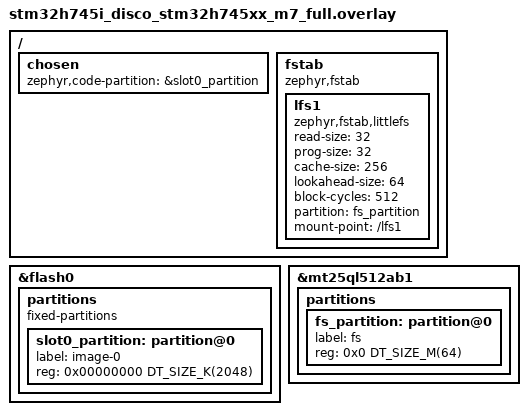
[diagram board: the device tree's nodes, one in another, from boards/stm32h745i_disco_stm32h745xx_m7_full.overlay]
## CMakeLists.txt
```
# SPDX-License-Identifier: Apache-2.0

cmake_minimum_required(VERSION 3.20.0)

option(CM_ENABLE_BOOTLOADER              "Enable bootloader support."                    OFF)
option(CM_ENABLE_CUSTOM_HEAP             "Enable custom heap."                           OFF)
option(CM_ENABLE_MEM_PROFILE             "Enable heap profiling."                        OFF)
option(CM_ENABLE_STACK_PROFILE           "Enable stack profiling."                       OFF)

if(DEFINED ENV{ZEPHYR_DNS_SERVER} OR DEFINED ENV{ZEPHYR_DNS_SERVER_2} OR DEFINED ENV{ZEPHYR_HOST_IP})
  set(EXTRA_CONF_CONTENT "")
  if(DEFINED ENV{ZEPHYR_DNS_SERVER})
    string(APPEND EXTRA_CONF_CONTENT "CONFIG_DNS_SERVER1=\"$ENV{ZEPHYR_DNS_SERVER}:53\"\n")
  endif()
  if(DEFINED ENV{ZEPHYR_DNS_SERVER_2})
    string(APPEND EXTRA_CONF_CONTENT "CONFIG_DNS_SERVER2=\"$ENV{ZEPHYR_DNS_SERVER_2}:53\"\n")
  endif()
  if(DEFINED ENV{ZEPHYR_HOST_IP})
    string(APPEND EXTRA_CONF_CONTENT "CONFIG_NET_CONFIG_PEER_IPV4_ADDR=\"$ENV{ZEPHYR_HOST_IP}\"\n")
  endif()
  set(ENV_CONF_FILE ${CMAKE_BINARY_DIR}/env_override.conf)
  file(WRITE ${ENV_CONF_FILE} ${EXTRA_CONF_CONTENT})
  set(CONF_FILE "prj.conf;${ENV_CONF_FILE}")
endif()

find_package(Zephyr REQUIRED HINTS $ENV{ZEPHYR_BASE})
project(trustedge_sample C)


set(MSS_DIR  "${CMAKE_CURRENT_SOURCE_DIR}/../../..")
set(MSS_SRC_DIR "${MSS_DIR}/src")
set(TRUSTCORE_LIB_DIR "${MSS_DIR}/bin_static")

include_directories(
  ${MSS_SRC_DIR}
  ${MSS_SRC_DIR}/trustedge
)

function(builder_add_flags FLAGS_VAR)
    message("----------------")
    foreach(FLAGS_FILE IN LISTS ARGN)
        message("${FLAGS_VAR} - adding flags in ${FLAGS_FILE}")
        file(STRINGS ${FLAGS_FILE} FLAGS_TO_ADD)
        set(FLAGS_LIST "${FLAGS_LIST} ${FLAGS_TO_ADD}")
    endforeach()
    set(${FLAGS_VAR} "${${FLAGS_VAR}} ${FLAGS_LIST}" PARENT_SCOPE)
endfunction()

function(builder_finalize_flags FLAGS_VAR)
    message("----------------")
    foreach(FLAG ${${FLAGS_VAR}})
        string(STRIP "${STRIPPED_FLAGS} ${FLAG}" STRIPPED_FLAGS)
    endforeach()
    set(${FLAGS_VAR} "${STRIPPED_FLAGS}" PARENT_SCOPE)
    message("${FLAGS_VAR} = ${${FLAGS_VAR}}")
endfunction()

if ("${BOARD}" STREQUAL "native_sim")
  add_definitions("-D__ENABLE_DIGICERT_NATIVE_SIM__")
elseif ("${BOARD}" STREQUAL "esp32s3_devkitc")
  add_definitions("-D__ENABLE_DIGICERT_ESP32S3__")
endif()

if (CM_ENABLE_BOOTLOADER)
  add_definitions("-D__ENABLE_DIGICERT_BOOTLOADER_SUPPORT__")
endif()

if (CM_ENABLE_MEM_PROFILE)
  add_definitions("-D__ENABLE_DIGICERT_MEM_PROFILE__")
endif()

if (CM_ENABLE_STACK_PROFILE)
  add_definitions("-D__ENABLE_DIGICERT_STACK_PROFILE__")
endif()

if (CM_ENABLE_CUSTOM_HEAP)
  add_definitions("-D__ENABLE_DIGICERT_CUSTOM_MALLOC__")
endif()

target_compile_definitions(app PRIVATE "-DIMAGE_NAME=\"${TRUSTEDGE_IMAGE_NAME}\"")

builder_add_flags(MOCANA_FLAGS "${CMAKE_CURRENT_SOURCE_DIR}/digicert_flags.txt")
builder_finalize_flags(MOCANA_FLAGS)

add_definitions("${MOCANA_FLAGS}")

# Add optimization compile options
  # target_compile_options(app PUBLIC
  #   -Oz
  #   -ffunction-sections
  #   -fdata-sections
  #   -flto
  #   -fmerge-all-constants
  #   -fno-jump-tables
  #   -fno-tree-switch-conversion
  #   -finline-functions
  #   -finline-small-functions
  # )

# Add optimization link options
  # target_link_options(app PUBLIC
  #   -Wl,--gc-sections
  #   -Wl,--relax
  #   -Wl,--sort-section=alignment
  #   -Wl,--sort-common
  #   -Wl,--strip-discarded
  #   -Wl,--orphan-handling=place
  #   -Wl,--print-memory-usage
  # )

if("${BOARD}" STREQUAL "esp32s3_devkitc")
  target_link_options(app PUBLIC
    -Wl,--wrap=malloc
    -Wl,--wrap=free
    -Wl,--wrap=calloc
    -Wl,--wrap=TRUSTEDGE_utilsGetHostByName
  )
endif()

set(app_sources src/main.c src/dns.c)
target_sources(app PRIVATE ${app_sources})

if("${BOARD}" STREQUAL "esp32s3_devkitc")
  target_sources(app PRIVATE src/heap_allocator.c)
endif()

file(GLOB EXTERNAL_LIBS "${TRUSTCORE_LIB_DIR}/*.a")

foreach(lib_path ${EXTERNAL_LIBS})
  get_filename_component(lib_name ${lib_path} NAME_WE)
  message(STATUS "Linking library: ${lib_name} => ${lib_path}")

  add_library(${lib_name} STATIC IMPORTED GLOBAL)
  set_target_properties(${lib_name} PROPERTIES IMPORTED_LOCATION ${lib_path})
  target_link_libraries(app PUBLIC ${lib_name})
endforeach()
```

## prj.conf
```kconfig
# Set the name of target binary
CONFIG_KERNEL_BIN_NAME="trustedge"
#CONFIG_DEBUG=y
#CONFIG_SIZE_OPTIMIZATIONS_AGGRESSIVE=y

# the number of bytes in the arena for C library malloc
CONFIG_COMMON_LIBC_MALLOC=y
#CONFIG_COMMON_LIBC_MALLOC_ARENA_SIZE=102000

CONFIG_REQUIRES_FULL_LIBC=y

CONFIG_ENTROPY_GENERATOR=y
CONFIG_TEST_RANDOM_GENERATOR=y

CONFIG_POSIX_API=y

# for enabling poxis threads
CONFIG_POSIX_THREADS=y # pthread
CONFIG_POSIX_TIMERS=y

CONFIG_INIT_STACKS=y
CONFIG_THREAD_STACK_INFO=y

CONFIG_DYNAMIC_THREAD=y
CONFIG_DYNAMIC_THREAD_POOL_SIZE=6
CONFIG_POSIX_THREAD_KEYS_MAX=20
CONFIG_POSIX_THREAD_THREADS_MAX=20
CONFIG_MAX_PTHREAD_MUTEX_COUNT=20
CONFIG_MAX_PTHREAD_COND_COUNT=20

# Enable thread awareness for debugging tools supporting it
CONFIG_DEBUG_THREAD_INFO=y

CONFIG_LOG=y

CONFIG_SHELL=y
CONFIG_SHELL_LOG_LEVEL_INF=y

CONFIG_FILE_SYSTEM=y
CONFIG_FILE_SYSTEM_SHELL=y

CONFIG_FILE_SYSTEM_LITTLEFS=y
CONFIG_FLASH_MAP=y
CONFIG_FLASH=y

# Networking config
#CONFIG_NET_SOCKETS_LOG_LEVEL_DBG=n
CONFIG_NET_SOCKETS=y
CONFIG_NETWORKING=y
CONFIG_NET_IPV4=y
CONFIG_NET_DHCPV4=y
CONFIG_NET_IPV6=n
CONFIG_NET_IF_MAX_IPV4_COUNT=2
CONFIG_NET_TCP=y
CONFIG_NET_LOG=n
CONFIG_NET_MAX_CONTEXTS=10

CONFIG_NET_SHELL=y

CONFIG_NET_CONFIG_SETTINGS=y
CONFIG_NET_CONFIG_NEED_IPV4=y

CONFIG_NET_MAX_CONN=10

CONFIG_ZVFS_POLL_MAX=10
CONFIG_ZVFS_OPEN_MAX=10
# Enable the DNS resolver
CONFIG_DNS_RESOLVER=y
# Enable additional buffers
CONFIG_DNS_RESOLVER_ADDITIONAL_BUF_CTR=5
# Enable additional queries
CONFIG_DNS_RESOLVER_ADDITIONAL_QUERIES=2
# Enable mDNS support
CONFIG_MDNS_RESOLVER=y
# Enable LLMNR support
CONFIG_LLMNR_RESOLVER=n

CONFIG_DNS_RESOLVER_MAX_SERVERS=2
CONFIG_DNS_SERVER_IP_ADDRESSES=y
CONFIG_DNS_NUM_CONCUR_QUERIES=5

CONFIG_DNS_SERVER1="8.8.8.8:53"
CONFIG_DNS_SERVER2="1.1.1.1:53"

CONFIG_NET_PKT_RX_COUNT=32
CONFIG_NET_PKT_TX_COUNT=32
CONFIG_NET_BUF_RX_COUNT=32
CONFIG_NET_BUF_TX_COUNT=32

CONFIG_NET_TCP_LOG_LEVEL_DBG=n

CONFIG_HWINFO=y

# Set current time from ntp server
CONFIG_SNTP=y
CONFIG_SNTP_LOG_LEVEL_DBG=n
CONFIG_NET_CONFIG_CLOCK_SNTP_INIT=y
CONFIG_NET_CONFIG_SNTP_INIT_RESYNC=y
CONFIG_NET_CONFIG_SNTP_INIT_SERVER="north-america.pool.ntp.org"

CONFIG_FRAME_POINTER=y

CONFIG_THREAD_NAME=y
#CONFIG_THREAD_ANALYZER=y
#CONFIG_THREAD_ANALYZER_AUTO=y
#CONFIG_THREAD_ANALYZER_RUN_UNLOCKED=y
```

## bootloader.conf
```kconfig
CONFIG_BOOTLOADER_MCUBOOT=y
CONFIG_MCUBOOT_SIGNATURE_KEY_FILE="bootloader/mcuboot/root-rsa-2048.pem"

# CONFIG_IMG_MANAGER depends on this
CONFIG_STREAM_FLASH=y

# CONFIG_MCUBOOT_IMG_MANAGER depends on this, already set above
CONFIG_FLASH_MAP=y

# required for including <zephyr/dfu/mcuboot.h>
CONFIG_IMG_MANAGER=y
CONFIG_MCUBOOT_IMG_MANAGER=y

CONFIG_IMG_BLOCK_BUF_SIZE=32

CONFIG_IMG_ENABLE_IMAGE_CHECK=y
#CONFIG_IMG_ENABLE_IMAGE_CHECK=y
CONFIG_MCUBOOT_UTIL_LOG_LEVEL_DBG=y
#CONFIG_IMG_MANAGER=y
```

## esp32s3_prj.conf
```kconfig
CONFIG_ESP_SPIRAM_HEAP_SIZE=4194304
CONFIG_COMMON_LIBC_MALLOC=n
CONFIG_HEAP_MEM_POOL_SIZE=25000
CONFIG_DYNAMIC_THREAD=y
CONFIG_DYNAMIC_THREAD_POOL_SIZE=4
CONFIG_DYNAMIC_THREAD_ALLOC=y
CONFIG_DYNAMIC_THREAD_STACK_SIZE=8000
CONFIG_MAIN_STACK_SIZE=8192
CONFIG_STACK_CANARIES=y
CONFIG_STACK_SENTINEL=y
CONFIG_SHELL_BACKEND_SERIAL_TX_RING_BUFFER_SIZE=192
CONFIG_SHELL_BACKEND_SERIAL_RX_RING_BUFFER_SIZE=192
CONFIG_SYSTEM_WORKQUEUE_STACK_SIZE=4096
CONFIG_LOG_PROCESS_THREAD_STACK_SIZE=4096
CONFIG_SHELL_STACK_SIZE=5500
CONFIG_LOG_BUFFER_SIZE=8192
CONFIG_LOG_FUNC_NAME_PREFIX_DBG=n
CONFIG_SHELL_LOG_BACKEND=y
CONFIG_LOG_PROCESS_TRIGGER_THRESHOLD=1
CONFIG_LOG_BACKEND_FS=y
CONFIG_LOG_BACKEND_FS_AUTOSTART=n
CONFIG_LOG_BACKEND_FS_FILE_SIZE=1024000
CONFIG_LOG_BACKEND_FS_FILES_LIMIT=5
CONFIG_LOG_BACKEND_FS_DIR="/lfs1/log"
CONFIG_LOG_CMDS=y
CONFIG_INIT_STACKS=y
CONFIG_KERNEL_SHELL=y
CONFIG_THREAD_MONITOR=y
CONFIG_BOOT_BANNER=y
CONFIG_THREAD_NAME=y
CONFIG_DEVICE_SHELL=n
CONFIG_DATE_SHELL=n
CONFIG_IDLE_STACK_SIZE=1024
CONFIG_STATS=y
CONFIG_STATS_SHELL=y
CONFIG_SIZE_OPTIMIZATIONS_AGGRESSIVE=y
CONFIG_REBOOT=y
CONFIG_FS_LITTLEFS_READ_SIZE=1024
CONFIG_FS_LITTLEFS_PROG_SIZE=1024
CONFIG_FS_LITTLEFS_CACHE_SIZE=1024
CONFIG_FS_LITTLEFS_LOOKAHEAD_SIZE=512
CONFIG_FS_LITTLEFS_BLOCK_CYCLES=16
CONFIG_ESP_SPIRAM=y
CONFIG_ESP_SPIRAM_SIZE=8388608
CONFIG_SPIRAM_MODE_OCT=y
CONFIG_SHARED_MULTI_HEAP=y
CONFIG_ESP32S3_DATA_CACHE_64KB=y
CONFIG_ESP32S3_DATA_CACHE_LINE_64B=y
CONFIG_SPIRAM_TYPE_ESPPSRAM64=y
CONFIG_ESP32_WIFI_NET_ALLOC_SPIRAM=y
CONFIG_ESP_WIFI_HEAP_SPIRAM=y
CONFIG_BOOTLOADER_MCUBOOT=y
CONFIG_WIFI=y
CONFIG_NET_SHELL=y
CONFIG_SNTP=y
CONFIG_SNTP_LOG_LEVEL_INF=y
CONFIG_NET_CONFIG_CLOCK_SNTP_INIT=y
CONFIG_NET_CONFIG_SNTP_INIT_RESYNC=y
CONFIG_NET_CONNECTION_MANAGER=y
CONFIG_NET_CONFIG_SNTP_INIT_USE_CONNECTION_MANAGER=y
CONFIG_NET_CONFIG_SNTP_INIT_SERVER="time.google.com"
CONFIG_NET_DHCPV4=y
CONFIG_NET_LOG=y
CONFIG_NET_L2_WIFI_SHELL=y
CONFIG_DNS_RESOLVER=y
CONFIG_ESP32_WIFI_AMPDU_TX_ENABLED=y
CONFIG_ESP32_WIFI_TX_BA_WIN=32
CONFIG_NET_TCP_KEEPALIVE=y
CONFIG_NET_L2_WIFI_MGMT=y
CONFIG_NET_TCP_WORKQ_STACK_SIZE=8192
CONFIG_NET_TX_STACK_SIZE=8192
CONFIG_NET_RX_STACK_SIZE=8192
CONFIG_NET_BUF_RX_COUNT=512
CONFIG_NET_BUF_TX_COUNT=512
CONFIG_NET_PKT_RX_COUNT=512
CONFIG_NET_PKT_TX_COUNT=512
CONFIG_ESP32_WIFI_CACHE_TX_BUFFER_NUM=128


# CONFIG_ESP32_WIFI_DYNAMIC_TX_BUFFER=y
# CONFIG_ESP32_WIFI_DYNAMIC_TX_BUFFER_NUM=128
# CONFIG_ESP32_WIFI_DYNAMIC_RX_MGMT_BUFFER=y
# CONFIG_ESP32_WIFI_DYNAMIC_RX_BUFFER_NUM=128
# CONFIG_ESP32_WIFI_STATIC_TX_BUFFER=y
# CONFIG_ESP32_WIFI_STATIC_TX_BUFFER_NUM=64
# CONFIG_NET_CONNECTION_MANAGER=y
# CONFIG_NET_TCP_RECV_QUEUE_TIMEOUT=10000
# CONFIG_NET_TCP_MAX_SEND_WINDOW_SIZE=65535
# CONFIG_NET_TCP_MAX_RECV_WINDOW_SIZE=65535
# CONFIG_THREAD_ANALYZER=y
# CONFIG_THREAD_ANALYZER_AUTO=y
# CONFIG_THREAD_ANALYZER_AUTO_INTERVAL=5
# CONFIG_COMMON_LIBC_MALLOC_ARENA_SIZE=0
# CONFIG_NET_MAX_CONN=10
# CONFIG_NET_MAX_CONTEXTS=15
# CONFIG_ESP32_WIFI_CACHE_TX_BUFFER_NUM=64
# CONFIG_NET_STATISTICS=y
# CONFIG_NET_STATISTICS_WIFI=y
# CONFIG_NET_MGMT_EVENT_QUEUE_SIZE=10
# CONFIG_MDNS_RESOLVER=y
# CONFIG_NET_HOSTNAME_ENABLE=y
# CONFIG_NET_HOSTNAME="esp32-client"
# CONFIG_NET_DEBUG_NET_PKT_ALLOC=y
# CONFIG_FILE_SYSTEM_MKFS=y
# CONFIG_ESP32S3_UNIVERSAL_MAC_ADDRESSES_FOUR=y
# CONFIG_NET_IF_UNICAST_IPV4_ADDR_COUNT=2
# CONFIG_ESP32_WIFI_STA_AUTO_DHCPV4=y
# CONFIG_SPIRAM_FETCH_INSTRUCTIONS=y
# CONFIG_EARLY_CONSOLE=y
# CONFIG_NET_MGMT_EVENT_QUEUE_TIMEOUT=5000
# CONFIG_NET_MGMT_EVENT_QUEUE_SIZE=8
# CONFIG_POSIX_API=y
# CONFIG_POSIX_THREADS=y
# CONFIG_POSIX_TIMERS=y
# CONFIG_THREAD_STACK_INFO=y
# CONFIG_POSIX_THREAD_KEYS_MAX=20
# CONFIG_POSIX_THREAD_THREADS_MAX=20
# CONFIG_MAX_PTHREAD_MUTEX_COUNT=20
# CONFIG_MAX_PTHREAD_COND_COUNT=20
# CONFIG_DEBUG_THREAD_INFO=y
# CONFIG_LOG=y
# CONFIG_SHELL=y
# CONFIG_SHELL_LOG_LEVEL_INF=y
# CONFIG_FILE_SYSTEM=y
# CONFIG_FILE_SYSTEM_SHELL=y
# CONFIG_FILE_SYSTEM_LITTLEFS=y
# CONFIG_FLASH_MAP=y
# CONFIG_FLASH=y
# CONFIG_NET_SOCKETS_LOG_LEVEL_DBG=n
# CONFIG_NET_IF_MAX_IPV4_COUNT=2
# CONFIG_NET_CONFIG_SETTINGS=y
# CONFIG_NET_CONFIG_NEED_IPV4=y
# CONFIG_NET_CONFIG_MY_IPV4_ADDR="192.168.1.142"
# CONFIG_NET_CONFIG_PEER_IPV4_ADDR="192.168.1.124"
# CONFIG_NET_CONFIG_MY_IPV4_GW="192.168.1.1"
# CONFIG_PRINTK=y
# CONFIG_RTC=y
# CONFIG_ZTEST_STACK_SIZE=4096
# CONFIG_NET_TCP=y
# CONFIG_LOG_BACKEND_UART=y
# CONFIG_LOG_PROCESS_THREAD_CUSTOM_PRIORITY=y
# CONFIG_LOG_MODE_OVERFLOW=y
# CONFIG_LOG_MODE_DEFERRED=y
# CONFIG_LOG_RUNTIME_FILTERING=y
# CONFIG_ESP32_WIFI_DEBUG_PRINT=n
# CONFIG_ESP32_WIFI_CACHE_TX_BUFFER_NUM=16
# CONFIG_ESP32_WIFI_RX_BA_WIN=3
# CONFIG_SPIRAM_SPEED_80M=y
# CONFIG_ESPTOOLPY_FLASHFREQ_80M=y
# CONFIG_NET_SOCKETS=y
# CONFIG_DNS_SERVER1="172.16.23.141:53"
# CONFIG_NET_BUF_VARIABLE_DATA_SIZE=n
# CONFIG_NET_BUF=y
# CONFIG_NET_BUF_POOL_USAGE=y
# CONFIG_NET_PKT_BUF_RX_DATA_POOL_SIZE=16384
# CONFIG_NET_PKT_BUF_TX_DATA_POOL_SIZE=16384
# CONFIG_NET_BUF_FIXED_DATA_SIZE=y
# CONFIG_ZVFS_POLL_MAX=15
# CONFIG_ZVFS_OPEN_MAX=15
# CONFIG_NET_BUF_DATA_SIZE=512
```

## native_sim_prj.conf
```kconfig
# Set the name of target binary
CONFIG_KERNEL_BIN_NAME="trustedge"
CONFIG_DEBUG=n

# the number of bytes in the arena for C library malloc
CONFIG_COMMON_LIBC_MALLOC=y
CONFIG_COMMON_LIBC_MALLOC_ARENA_SIZE=1048576

CONFIG_REQUIRES_FULL_LIBC=y

# number of bytes for k_malloc
CONFIG_HEAP_MEM_POOL_SIZE=1048576

# Networking config
CONFIG_NET_SOCKETS=y
CONFIG_NETWORKING=y
CONFIG_ENTROPY_GENERATOR=y
CONFIG_TEST_RANDOM_GENERATOR=y
CONFIG_POSIX_SEMAPHORES=y
CONFIG_POSIX_AEP_CHOICE_PSE51=y
CONFIG_POSIX_MESSAGE_PASSING=y
CONFIG_POSIX_NETWORKING=y
CONFIG_POSIX_SIGNALS=y
CONFIG_POSIX_REALTIME_SIGNALS=y
CONFIG_POSIX_API=y
CONFIG_REBOOT=y

# for enabling poxis threads
CONFIG_POSIX_THREADS=y
CONFIG_THREAD_STACK_INFO=y
CONFIG_DYNAMIC_THREAD=y

CONFIG_DYNAMIC_THREAD_POOL_SIZE=20
CONFIG_POSIX_THREAD_KEYS_MAX=20
CONFIG_POSIX_THREAD_THREADS_MAX=20
CONFIG_MAX_PTHREAD_MUTEX_COUNT=20
CONFIG_MAX_PTHREAD_COND_COUNT=20

# Enable thread awareness for debugging tools supporting it
CONFIG_DEBUG_THREAD_INFO=y

CONFIG_LOG=y

CONFIG_FLASH=y

CONFIG_SHELL=y
CONFIG_SHELL_LOG_LEVEL_INF=y

CONFIG_FILE_SYSTEM=y
CONFIG_FILE_SYSTEM_SHELL=y

CONFIG_FILE_SYSTEM_LITTLEFS=y
CONFIG_FLASH_MAP=y

CONFIG_NET_SHELL=y

# Networking config
CONFIG_NET_IPV4=y
CONFIG_NET_IF_MAX_IPV4_COUNT=2
CONFIG_NET_IF_MAX_IPV6_COUNT=2
CONFIG_NET_TCP=y
CONFIG_NET_LOG=y

CONFIG_INIT_STACKS=y
# Network address config

CONFIG_NET_CONFIG_SETTINGS=y
CONFIG_NET_CONFIG_NEED_IPV4=y
CONFIG_NET_CONFIG_MY_IPV4_ADDR="10.166.125.155"
CONFIG_ETH_NATIVE_POSIX=n
CONFIG_NET_DRIVERS=y
CONFIG_NET_SOCKETS=y
CONFIG_NET_SOCKETS_OFFLOAD=y
CONFIG_NET_NATIVE_OFFLOADED_SOCKETS=y

CONFIG_DNS_RESOLVER=y
CONFIG_DNS_SERVER_IP_ADDRESSES=y
CONFIG_DNS_SERVER1="8.8.8.8"

CONFIG_HWINFO=y

CONFIG_MAIN_STACK_SIZE=4096

# RSA_setPublicKeyData had RSA_N optimized out
CONFIG_NO_OPTIMIZATIONS=y

# Set current time from ntp server
CONFIG_SNTP=y
CONFIG_NET_CONFIG_CLOCK_SNTP_INIT=y
CONFIG_NET_CONFIG_SNTP_INIT_RESYNC=y
CONFIG_POSIX_TIMERS=y
CONFIG_NET_CONFIG_SNTP_INIT_SERVER="north-america.pool.ntp.org"

# Assign a static MAC to device
CONFIG_ETH_NATIVE_POSIX_MAC_ADDR="00:11:22:33:44:55"
CONFIG_ETH_NATIVE_POSIX_RANDOM_MAC=n
```

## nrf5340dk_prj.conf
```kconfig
# Set the name of target binary
#CONFIG_KERNEL_BIN_NAME="trustedge"
#CONFIG_DEBUG=y
#CONFIG_SIZE_OPTIMIZATIONS_AGGRESSIVE=y

# heap and stack tracking requires additional file handles
CONFIG_FS_LITTLEFS_NUM_FILES=8
CONFIG_DYNAMIC_THREAD_STACK_SIZE=10240
CONFIG_MAIN_STACK_SIZE=10000

CONFIG_POSIX_MAX_FDS=32
CONFIG_ZVFS_OPEN_MAX=32

CONFIG_SYSTEM_WORKQUEUE_STACK_SIZE=8192
CONFIG_LOG_PROCESS_THREAD_STACK_SIZE=8192
CONFIG_SHELL_STACK_SIZE=8192

CONFIG_LOG_BACKEND_FS=y
CONFIG_LOG_BACKEND_FS_FILE_SIZE=1024000
CONFIG_LOG_BACKEND_FS_FILES_LIMIT=5
CONFIG_LOG_BACKEND_FS_DIR="/lfs1/log"

CONFIG_PRINTK=y
CONFIG_LOG_CMDS=y
CONFIG_INIT_STACKS=y
CONFIG_KERNEL_SHELL=y
CONFIG_THREAD_MONITOR=y
CONFIG_BOOT_BANNER=n
CONFIG_THREAD_NAME=y
CONFIG_DEVICE_SHELL=y
CONFIG_DATE_SHELL=y
CONFIG_THREAD_RUNTIME_STATS=y
CONFIG_THREAD_RUNTIME_STATS_USE_TIMING_FUNCTIONS=y
CONFIG_STATS=y
CONFIG_STATS_SHELL=y
```

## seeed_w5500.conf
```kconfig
CONFIG_SPI=y
CONFIG_GPIO=y
CONFIG_ETH_W5500=y
```

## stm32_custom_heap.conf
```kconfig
# the number of bytes in the arena for C library malloc
#CONFIG_COMMON_LIBC_MALLOC=y
CONFIG_COMMON_LIBC_MALLOC_ARENA_SIZE=20000

# heap and stack tracking requires additional file handles
CONFIG_HEAP_MEM_POOL_SIZE=191000
```

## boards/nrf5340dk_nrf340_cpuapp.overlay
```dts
/*
 * Copyright (c) 2023 S&C Electric Company <www.sandc.com>
 * Copyright (c) 2024 STMicroelectronics
 *
 * SPDX-License-Identifier: Apache-2.0
 */

 /delete-node/ &boot_partition;
 /delete-node/ &slot0_partition;
 /delete-node/ &slot1_partition;
 /delete-node/ &slot0_ns_partition;
 /delete-node/ &slot1_ns_partition;
 /delete-node/ &tfm_ps_partition;
 /delete-node/ &tfm_otp_partition;
 /delete-node/ &tfm_its_partition;
 /delete-node/ &storage_partition;

/ {
	chosen {
		zephyr,code-partition = &slot0_partition;
	};

	fstab {
		compatible = "zephyr,fstab";
		lfs1: lfs1 {
			compatible = "zephyr,fstab,littlefs";
			read-size = <32>;
			prog-size = <32>;
			cache-size = <256>;
			lookahead-size = <64>;
			block-cycles = <512>;
			partition = <&storage_partition>;
			mount-point = "/lfs1";
		};
	};
};

&flash0 {
	partitions {
		compatible = "fixed-partitions";
		#address-cells = <1>;
		#size-cells = <1>;

		slot0_partition: partition@0 {
			label = "image-0";
			reg = <0x00000000 DT_SIZE_K(710)>;
		};

		storage_partition: partition@B1800 {
			label = "storage";
			reg = <0x000B1800 DT_SIZE_K(10)>;
		};

		fs_partition: partition@B4000 {
			label = "fs";
			reg = <0x000B4000 DT_SIZE_K(304)>;
		};
	};
};
```

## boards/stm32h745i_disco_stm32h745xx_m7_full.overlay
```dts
/*
 * Copyright (c) 2023 S&C Electric Company <www.sandc.com>
 * Copyright (c) 2024 STMicroelectronics
 *
 * SPDX-License-Identifier: Apache-2.0
 */

/ {
	chosen {
		zephyr,code-partition = &slot0_partition;
	};

	fstab {
		compatible = "zephyr,fstab";
		lfs1: lfs1 {
			compatible = "zephyr,fstab,littlefs";
			read-size = <32>;
			prog-size = <32>;
			cache-size = <256>;
			lookahead-size = <64>;
			block-cycles = <512>;
			partition = <&fs_partition>;
			mount-point = "/lfs1";
		};
	};
};

&flash0 {
	partitions {
		compatible = "fixed-partitions";
		#address-cells = <1>;
		#size-cells = <1>;

		slot0_partition: partition@0 {
			label = "image-0";
			reg = <0x00000000 DT_SIZE_K(2048)>;
		};
	};
};

&mt25ql512ab1 {
	partitions {
		fs_partition: partition@0 {
			label = "fs";
			reg = <0x0 DT_SIZE_M(64)>;
		};
	};
};
```

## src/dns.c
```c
#include <stdint.h>
#include "dns.h"

DnsLookupEntry lookup_table[MAX_LOOKUPS];

void dnsLookupTableInit() {
    for(int i = 0; i < MAX_LOOKUPS; i++) {
        lookup_table[i].status = DNS_SLOT_OPEN;
        k_mutex_init(&(lookup_table[i].lock));
    }
}

#define DNS_TIMEOUT (5 * MSEC_PER_SEC)

void dns_result_cb(enum dns_resolve_status status,
		   struct dns_addrinfo *info,
		   void *user_data)
{
	char *hr_family;
	void *addr;
    int index = (int)(intptr_t)user_data;
    DnsLookupEntry *pEntry = &lookup_table[index];

	printk("lookup table index=%d\n", index);
	switch (status) {
	case DNS_EAI_CANCELED:
		printk("DNS query was canceled\n");
		return;
	case DNS_EAI_FAIL:
		printk("DNS resolve failed\n");
		return;
	case DNS_EAI_NODATA:
		printk("Cannot resolve address\n");
		return;
	case DNS_EAI_ALLDONE:
		printk("DNS resolving finished\n");
        k_sem_give(&(pEntry->semaphore));
		return;
	case DNS_EAI_INPROGRESS:
		break;
	default:
		printk("DNS resolving error (%d)\n", status);
		return;
	}

	if (!info) {
		return;
	}

	if (info->ai_family == AF_INET) {
		hr_family = "IPv4";
		addr = &net_sin(&info->ai_addr)->sin_addr;
	} else if (info->ai_family == AF_INET6) {
		hr_family = "IPv6";
		addr = &net_sin6(&info->ai_addr)->sin6_addr;
	} else {
		printk("Invalid IP address family %d\n", info->ai_family);
		return;
	}

    k_mutex_lock(&(pEntry->lock), K_FOREVER);
    net_addr_ntop(info->ai_family, addr, pEntry->ip, IP_MAX);
    pEntry->status = DNS_RESOLVED;
    k_mutex_unlock(&(pEntry->lock));
}

int startDnsLookup(char *pName, char *pIPStr)
{
    int ret;
    int i;

    if (NULL == pName || NULL == pIPStr)
    {
        return -1;
    }

    if ((strcmp(pName, "localhost") == 0) || (strcmp(pName, "provision.digicert.com") == 0))
    {
        strcpy(pIPStr, "172.18.209.115");
        return 0;
    }

    /* is pNamed already cached? */
    for (i = 0; i < MAX_LOOKUPS; i++)
    {
        k_mutex_lock(&(lookup_table[i].lock), K_FOREVER);
        if ((lookup_table[i].status == DNS_RESOLVED) &&
            (strncmp(lookup_table[i].hostname, pName, HOSTNAME_MAX) == 0))
        {
            strncpy(pIPStr, lookup_table[i].ip, IP_MAX);
            printk("%s IPv4 address: %s\n", pName, pIPStr);
            k_mutex_unlock(&(lookup_table[i].lock));
            return 0;
        }
        k_mutex_unlock(&(lookup_table[i].lock));
    }

    for (i = 0; i < MAX_LOOKUPS; i++)
    {
        k_mutex_lock(&(lookup_table[i].lock), K_FOREVER);
        if (DNS_SLOT_OPEN == lookup_table[i].status)
        {
            k_sem_init(&(lookup_table[i].semaphore), 0, 1);
            strncpy(lookup_table[i].hostname, pName, HOSTNAME_MAX - 1);
            lookup_table[i].hostname[HOSTNAME_MAX - 1] = '\0';
            ret = dns_get_addr_info(pName,
                    DNS_QUERY_TYPE_A,
                    NULL,
                    dns_result_cb,
                    (void *)(intptr_t)i,
                    DNS_TIMEOUT);
            if (ret == 0) {
                lookup_table[i].status = DNS_PENDING;
            } else {
                printk("Cannot resolve IPv4ress (%d)\n", ret);
                k_sem_give(&(lookup_table[i].semaphore));
            }
            k_mutex_unlock(&(lookup_table[i].lock));
            break;
        }
        k_mutex_unlock(&(lookup_table[i].lock));
    }

    if (i >= MAX_LOOKUPS) {
        printk("DNS lookup table full\n");
        return -ENOMEM;
    }

    /* wait for signal that lookup is complete or timed out */
    k_sem_take(&(lookup_table[i].semaphore), K_MSEC(DNS_TIMEOUT));
    k_mutex_lock(&(lookup_table[i].lock), K_FOREVER);
    ret = -1;
    if (lookup_table[i].status == DNS_RESOLVED)
    {
        strncpy(pIPStr, lookup_table[i].ip, IP_MAX);
        printk("%s IPv4 address: %s\n", pName, pIPStr);
        ret = 0;
    }
    else
    {
        printk("DNS lookup for %s IPv4 address failed\n", pName);
        lookup_table[i].status = DNS_SLOT_OPEN;
        lookup_table[i].hostname[0] = '\0';
        lookup_table[i].ip[0] = '\0';
    }

    k_mutex_unlock(&(lookup_table[i].lock));
    return ret;
}
```

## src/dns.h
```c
#ifndef DIGI_DNS_SAMPLE_H
#define DIGI_DNS_SAMPLE_H

#include <zephyr/net/dns_resolve.h>
#include <zephyr/kernel.h>

#define MAX_LOOKUPS     8
#define HOSTNAME_MAX    DNS_MAX_NAME_SIZE
#define IP_MAX          40

typedef enum {
    DNS_SLOT_OPEN = -1,
    DNS_PENDING,
    DNS_RESOLVED
} DnsStatus;

typedef struct {
    char hostname[HOSTNAME_MAX];
    char ip[IP_MAX];
    DnsStatus status;
    struct k_mutex lock;
    struct k_sem semaphore; /* used to signal lookup is complete */
} DnsLookupEntry;

void dnsLookupTableInit(void);

/* extern used API */
int startDnsLookup(char *pName, char *pIPStr);

#endif
```

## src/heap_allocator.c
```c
#include <zephyr/kernel.h>
#include <zephyr/multi_heap/shared_multi_heap.h>
#include <zephyr/logging/log.h>

#define __RTOS_ZEPHYR__
#define __RTOS_LINUX__

#include <string.h>
#include "common/moptions.h"
#include "common/mtypes.h"
#include "common/merrors.h"

extern void *__real_malloc(size_t size);
extern void *__real_calloc(size_t nmemb, size_t size);
extern void __real_free(void *ptr);
extern MSTATUS __real_TRUSTEDGE_utilsGetHostByName(signed char *pName, signed char *pIpStr);

#define SPIRAM_THRESHOLD 2
#define MAX_TRACKED_ALLOCS 10000

static volatile uint32_t total_mallocs = 0;
static volatile uint32_t total_frees = 0;
static volatile uint32_t tracking_failures = 0;

__attribute__((section(".ext_ram.bss")))
static volatile struct
{
    void *ptr;
    uint32_t magic;
} alloc_tracking[MAX_TRACKED_ALLOCS];

#define SPIRAM_MAGIC 0xDEADBEEF
#define DRAM_MAGIC   0xCAFEBABE
#define SLOT_DELETED ((void*)1)
#define SPIRAM_DEBUG_LOG 0

static struct k_spinlock tracking_lock;

static inline bool is_spiram_ptr(void *ptr)
{
    if (!ptr)
    {
        return false;
    }

    uintptr_t addr = (uintptr_t)ptr;
    return (addr >= 0x3c000000 && addr < 0x3e000000);
}

static void track_allocation(void *ptr, bool is_spiram) {
    if (!ptr)
    {
        return;
    }

    if (k_is_in_isr())
    {
        return;
    }

    total_mallocs++;

    k_spinlock_key_t key = k_spin_lock(&tracking_lock);

    uint32_t hash = ((uintptr_t)ptr >> 3) % MAX_TRACKED_ALLOCS;
    uint32_t attempts = 0;

    while (attempts < MAX_TRACKED_ALLOCS)
    {
        if (alloc_tracking[hash].ptr == NULL || alloc_tracking[hash].ptr == SLOT_DELETED)
        {
            alloc_tracking[hash].ptr = ptr;
            alloc_tracking[hash].magic = is_spiram ? SPIRAM_MAGIC : DRAM_MAGIC;
            k_spin_unlock(&tracking_lock, key);
            return;
        }

        hash = (hash + 1) % MAX_TRACKED_ALLOCS;
        attempts++;
    }

    tracking_failures++;
#if SPIRAM_DEBUG_LOG
    printk("Tracking table full, allocation %p not tracked (failures: %u)\n", ptr, tracking_failures);
#endif
    k_spin_unlock(&tracking_lock, key);
}

static bool find_and_remove_allocation(void *ptr) {
    if (!ptr)
    {
        return false;
    }

    if (k_is_in_isr())
    {
        return is_spiram_ptr(ptr);
    }

    total_frees++;

    k_spinlock_key_t key = k_spin_lock(&tracking_lock);

    uint32_t hash = ((uintptr_t)ptr >> 3) % MAX_TRACKED_ALLOCS;
    uint32_t attempts = 0;

    while (attempts < MAX_TRACKED_ALLOCS)
    {
        if (alloc_tracking[hash].ptr == ptr)
        {
            bool was_spiram = (alloc_tracking[hash].magic == SPIRAM_MAGIC);
            alloc_tracking[hash].ptr = SLOT_DELETED;
            alloc_tracking[hash].magic = 0;
            k_spin_unlock(&tracking_lock, key);
            return was_spiram;
        }

        if (alloc_tracking[hash].ptr == NULL)
        {
            break;
        }

        hash = (hash + 1) % MAX_TRACKED_ALLOCS;
        attempts++;
    }

    k_spin_unlock(&tracking_lock, key);

    bool is_spiram = is_spiram_ptr(ptr);
#if SPIRAM_DEBUG_LOG
    printk("Allocation %p not tracked, using address check: %s (mallocs: %u, frees: %u)\n",
            ptr, is_spiram ? "SPIRAM" : "DRAM", total_mallocs, total_frees);
#endif
    return is_spiram;
}

void *__wrap_malloc(size_t size)
{
    void *ptr = NULL;
    if (size == 0)
    {
        return NULL;
    }

    ptr = shared_multi_heap_alloc(SMH_REG_ATTR_EXTERNAL, size);
    if (ptr)
    {
        track_allocation(ptr, true);
#if SPIRAM_DEBUG_LOG
        printk("SPIRAM malloc: %p (%zu bytes)\n", ptr, size);
#endif
        return ptr;
    }

    ptr = __real_malloc(size);
    if (ptr)
    {
        track_allocation(ptr, false);
#if SPIRAM_DEBUG_LOG
        printk("DRAM malloc: %p (%zu bytes)\n", ptr, size);
#endif
    }
    else
    {
#if SPIRAM_DEBUG_LOG
        printk("malloc failed for %zu bytes\n", size);
#endif
    }

    return ptr;
}

void *__wrap_calloc(size_t nmemb, size_t size)
{
    void *ptr = NULL;
    if (nmemb == 0 || size == 0)
    {
        return NULL;
    }

    if (nmemb > SIZE_MAX / size)
    {
#if SPIRAM_DEBUG_LOG
        printk("calloc overflow: %zu * %zu\n", nmemb, size);
#endif
        return NULL;
    }

    size_t total_size = nmemb * size;

    ptr = shared_multi_heap_alloc(SMH_REG_ATTR_EXTERNAL, total_size);
    if (ptr)
    {
        memset(ptr, 0, total_size);
        track_allocation(ptr, true);
#if SPIRAM_DEBUG_LOG
        printk("SPIRAM calloc: %p (%zu bytes)\n", ptr, total_size);
#endif
        return ptr;
    }

    ptr = __real_calloc(nmemb, size);
    if (ptr)
    {
        track_allocation(ptr, false);
#if SPIRAM_DEBUG_LOG
        printk("DRAM calloc: %p (%zu bytes)\n", ptr, total_size);
#endif
    }
    else
    {
#if SPIRAM_DEBUG_LOG
        printk("calloc failed for %zu bytes\n", total_size);
#endif
    }

    return ptr;
}

void __wrap_free(void *ptr)
{
    if (!ptr)
    {
        return;
    }

    bool was_spiram = find_and_remove_allocation(ptr);

    if (was_spiram)
    {
        shared_multi_heap_free(ptr);
#if SPIRAM_DEBUG_LOG
        printk("SPIRAM free: %p\n", ptr);
#endif
    }
    else
    {
        __real_free(ptr);
#if SPIRAM_DEBUG_LOG
        printk("DRAM free: %p\n", ptr);
#endif
    }
}

MSTATUS __wrap_TRUSTEDGE_utilsGetHostByName(signed char *hostname, signed char *addr)
{
    MSTATUS status = OK;
    if (hostname && strcmp(hostname, "provision.digicert.com") == 0) {
        const char *configured_ip = CONFIG_NET_CONFIG_PEER_IPV4_ADDR;

        if (!configured_ip || strlen(configured_ip) == 0) {
            return __real_TRUSTEDGE_utilsGetHostByName(hostname, addr);
        }

        strcpy(addr, configured_ip);
        return status;
    }

    return __real_TRUSTEDGE_utilsGetHostByName(hostname, addr);
}
```
